# PIC32MZ2051W104132 device description
Architecture: MIPS; Family: PIC32MZW; Series: PIC32MZW
Registers are 32-bit, read-write, no defined reset value unless marked. A register's access mark holds for its fields unless they carry their own. Offsets are from the block's base; [hi:lo] are bit positions; {n}, {i} and the like mark numbered series; 'fields as' and 'values as' point back to an identical list.

## GPIO
Instances: GPIO 0x1f820000 in periph_pb2
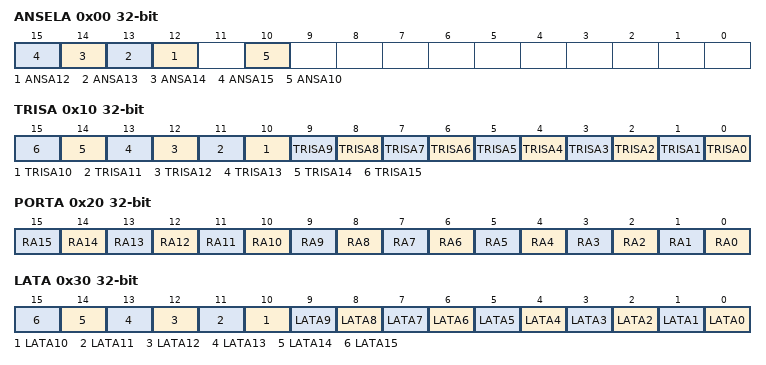
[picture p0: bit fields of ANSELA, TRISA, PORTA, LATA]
0x00 ANSELA
  [n] ANSA{n} (n=12..15), [10] ANSA10
0x10 TRISA
  [n] TRISA{n} (n=0..15)
0x20 PORTA
  [n] RA{n} (n=0..15)
0x30 LATA
  [n] LATA{n} (n=0..15)
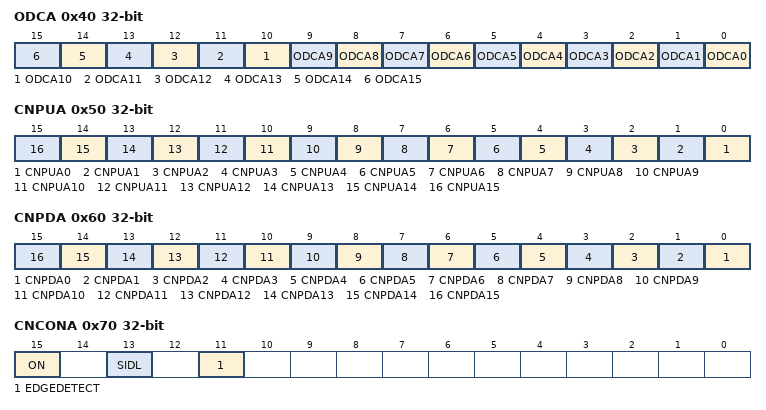
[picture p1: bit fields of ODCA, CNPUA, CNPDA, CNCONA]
0x40 ODCA
  [n] ODCA{n} (n=0..15)
0x50 CNPUA
  [n] CNPUA{n} (n=0..15)
0x60 CNPDA
  [n] CNPDA{n} (n=0..15)
0x70 CNCONA — Change Notice control for PORTx Register
  [15] ON — Change Notice Control ON bit
    1=CN is enabled; 0=CN is disabled
  [13] SIDL
  [11] EDGEDETECT — Change Notification Style bit
    1=Edge Style. Detect edge transitions (CNFx used for CN Event).; 0=Mismatch Style. Detect change from last PORTx read (CNSTATx used for CN Event).
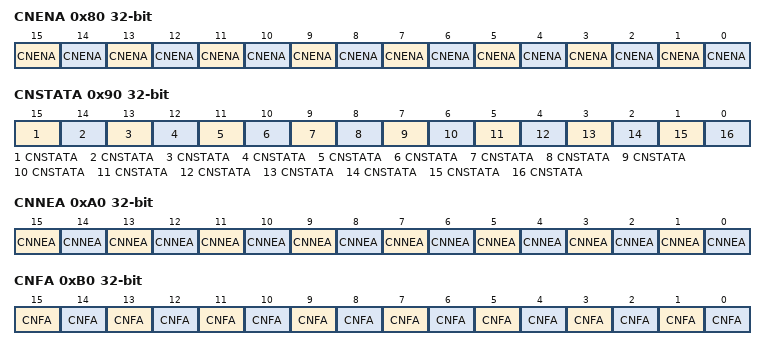
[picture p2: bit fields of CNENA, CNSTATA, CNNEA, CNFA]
0x80 CNENA
  [15] CNENA, [14] CNENA, [13] CNENA, [12] CNENA, [11] CNENA, [10] CNENA, [9] CNENA, [8] CNENA, [7] CNENA, [6] CNENA, [5] CNENA, [4] CNENA, [3] CNENA, [2] CNENA, [1] CNENA, [0] CNENA
0x90 CNSTATA
  [15] CNSTATA, [14] CNSTATA, [13] CNSTATA, [12] CNSTATA, [11] CNSTATA, [10] CNSTATA, [9] CNSTATA, [8] CNSTATA, [7] CNSTATA, [6] CNSTATA, [5] CNSTATA, [4] CNSTATA, [3] CNSTATA, [2] CNSTATA, [1] CNSTATA, [0] CNSTATA
0xA0 CNNEA
  [15] CNNEA, [14] CNNEA, [13] CNNEA, [12] CNNEA, [11] CNNEA, [10] CNNEA, [9] CNNEA, [8] CNNEA, [7] CNNEA, [6] CNNEA, [5] CNNEA, [4] CNNEA, [3] CNNEA, [2] CNNEA, [1] CNNEA, [0] CNNEA
0xB0 CNFA
  [15] CNFA, [14] CNFA, [13] CNFA, [12] CNFA, [11] CNFA, [10] CNFA, [9] CNFA, [8] CNFA, [7] CNFA, [6] CNFA, [5] CNFA, [4] CNFA, [3] CNFA, [2] CNFA, [1] CNFA, [0] CNFA
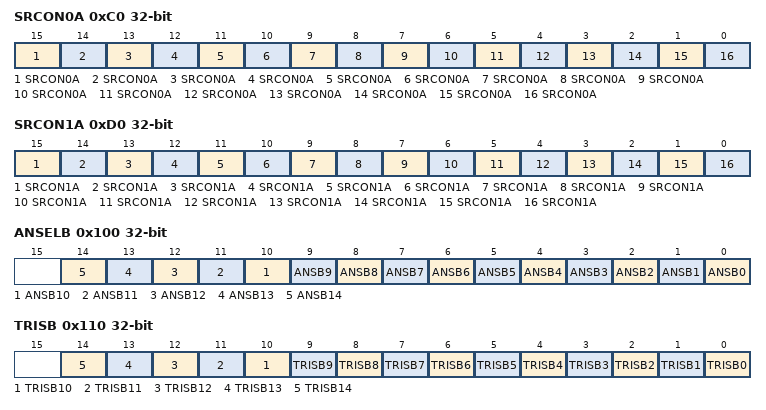
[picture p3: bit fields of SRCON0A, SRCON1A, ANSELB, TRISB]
0xC0 SRCON0A
  [15] SRCON0A, [14] SRCON0A, [13] SRCON0A, [12] SRCON0A, [11] SRCON0A, [10] SRCON0A, [9] SRCON0A, [8] SRCON0A, [7] SRCON0A, [6] SRCON0A, [5] SRCON0A, [4] SRCON0A, [3] SRCON0A, [2] SRCON0A, [1] SRCON0A, [0] SRCON0A
0xD0 SRCON1A
  [15] SRCON1A, [14] SRCON1A, [13] SRCON1A, [12] SRCON1A, [11] SRCON1A, [10] SRCON1A, [9] SRCON1A, [8] SRCON1A, [7] SRCON1A, [6] SRCON1A, [5] SRCON1A, [4] SRCON1A, [3] SRCON1A, [2] SRCON1A, [1] SRCON1A, [0] SRCON1A
0x100 ANSELB
  [n] ANSB{n} (n=0..14)
0x110 TRISB
  [n] TRISB{n} (n=0..14)
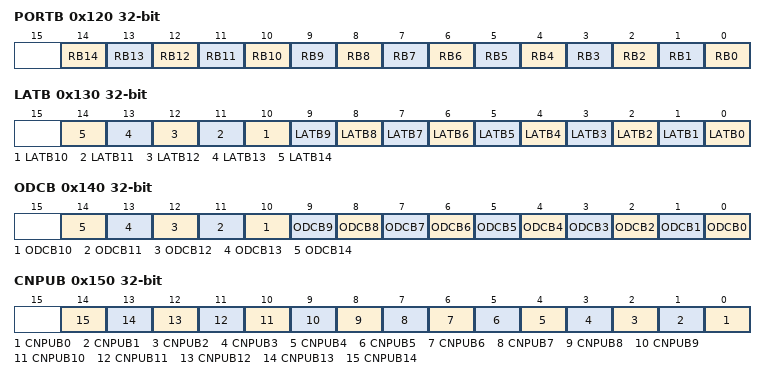
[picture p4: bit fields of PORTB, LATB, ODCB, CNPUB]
0x120 PORTB
  [n] RB{n} (n=0..14)
0x130 LATB
  [n] LATB{n} (n=0..14)
0x140 ODCB
  [n] ODCB{n} (n=0..14)
0x150 CNPUB
  [n] CNPUB{n} (n=0..14)
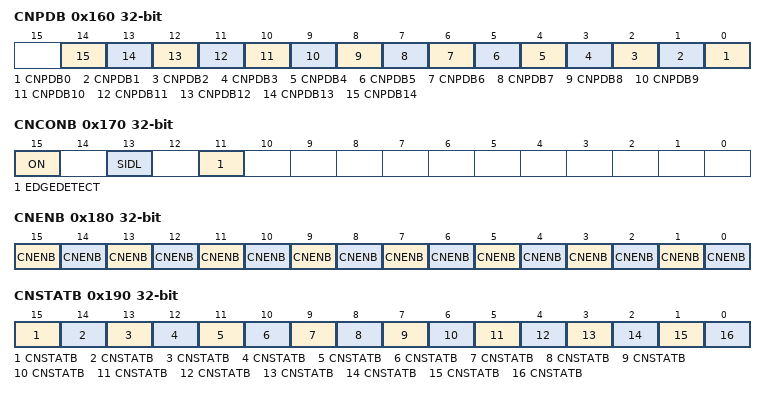
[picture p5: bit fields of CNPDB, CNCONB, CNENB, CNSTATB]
0x160 CNPDB
  [n] CNPDB{n} (n=0..14)
0x170 CNCONB — Change Notice control for PORTx Register
  fields as CNCONA
0x180 CNENB
  [15] CNENB, [14] CNENB, [13] CNENB, [12] CNENB, [11] CNENB, [10] CNENB, [9] CNENB, [8] CNENB, [7] CNENB, [6] CNENB, [5] CNENB, [4] CNENB, [3] CNENB, [2] CNENB, [1] CNENB, [0] CNENB
0x190 CNSTATB
  [15] CNSTATB, [14] CNSTATB, [13] CNSTATB, [12] CNSTATB, [11] CNSTATB, [10] CNSTATB, [9] CNSTATB, [8] CNSTATB, [7] CNSTATB, [6] CNSTATB, [5] CNSTATB, [4] CNSTATB, [3] CNSTATB, [2] CNSTATB, [1] CNSTATB, [0] CNSTATB
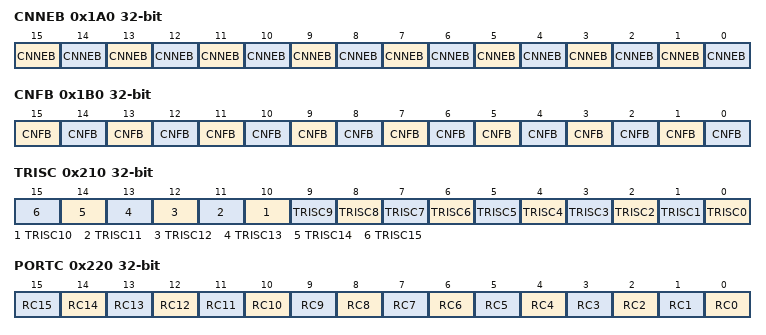
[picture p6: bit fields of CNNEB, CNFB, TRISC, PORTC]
0x1A0 CNNEB
  [15] CNNEB, [14] CNNEB, [13] CNNEB, [12] CNNEB, [11] CNNEB, [10] CNNEB, [9] CNNEB, [8] CNNEB, [7] CNNEB, [6] CNNEB, [5] CNNEB, [4] CNNEB, [3] CNNEB, [2] CNNEB, [1] CNNEB, [0] CNNEB
0x1B0 CNFB
  [15] CNFB, [14] CNFB, [13] CNFB, [12] CNFB, [11] CNFB, [10] CNFB, [9] CNFB, [8] CNFB, [7] CNFB, [6] CNFB, [5] CNFB, [4] CNFB, [3] CNFB, [2] CNFB, [1] CNFB, [0] CNFB
0x210 TRISC
  [n] TRISC{n} (n=0..15)
0x220 PORTC
  [n] RC{n} (n=0..15)
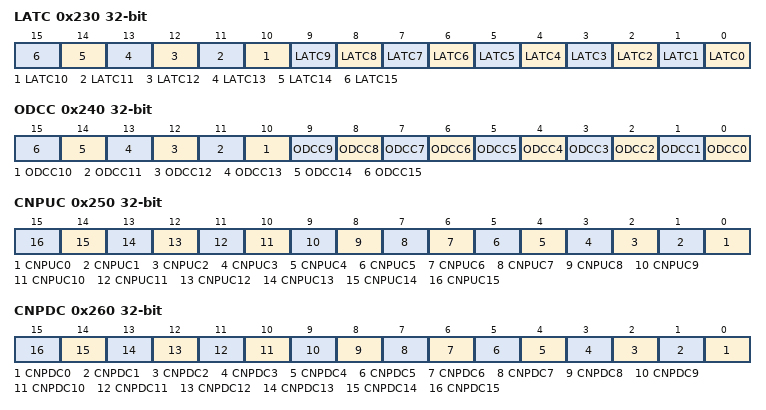
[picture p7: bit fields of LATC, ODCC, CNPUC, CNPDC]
0x230 LATC
  [n] LATC{n} (n=0..15)
0x240 ODCC
  [n] ODCC{n} (n=0..15)
0x250 CNPUC
  [n] CNPUC{n} (n=0..15)
0x260 CNPDC
  [n] CNPDC{n} (n=0..15)
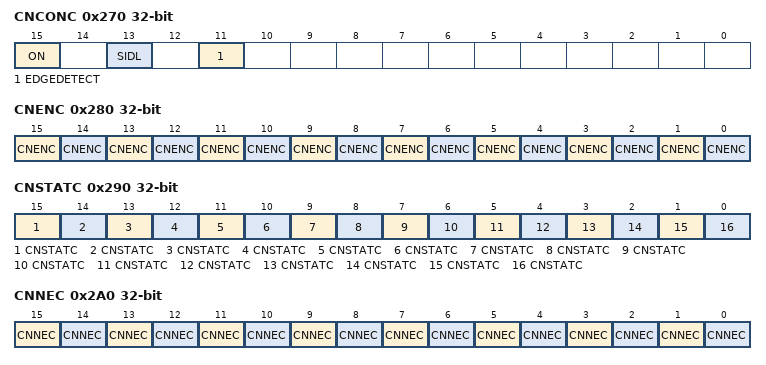
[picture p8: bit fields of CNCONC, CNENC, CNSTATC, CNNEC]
0x270 CNCONC — Change Notice control for PORTx Register
  fields as CNCONA
0x280 CNENC
  [15] CNENC, [14] CNENC, [13] CNENC, [12] CNENC, [11] CNENC, [10] CNENC, [9] CNENC, [8] CNENC, [7] CNENC, [6] CNENC, [5] CNENC, [4] CNENC, [3] CNENC, [2] CNENC, [1] CNENC, [0] CNENC
0x290 CNSTATC
  [15] CNSTATC, [14] CNSTATC, [13] CNSTATC, [12] CNSTATC, [11] CNSTATC, [10] CNSTATC, [9] CNSTATC, [8] CNSTATC, [7] CNSTATC, [6] CNSTATC, [5] CNSTATC, [4] CNSTATC, [3] CNSTATC, [2] CNSTATC, [1] CNSTATC, [0] CNSTATC
0x2A0 CNNEC
  [15] CNNEC, [14] CNNEC, [13] CNNEC, [12] CNNEC, [11] CNNEC, [10] CNNEC, [9] CNNEC, [8] CNNEC, [7] CNNEC, [6] CNNEC, [5] CNNEC, [4] CNNEC, [3] CNNEC, [2] CNNEC, [1] CNNEC, [0] CNNEC
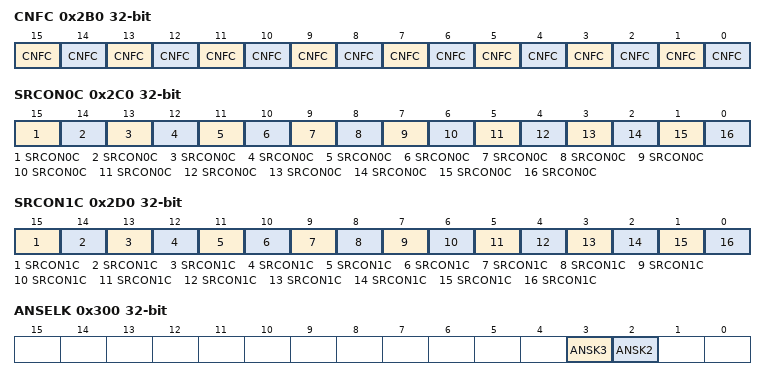
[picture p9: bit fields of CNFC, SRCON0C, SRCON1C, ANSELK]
0x2B0 CNFC
  [15] CNFC, [14] CNFC, [13] CNFC, [12] CNFC, [11] CNFC, [10] CNFC, [9] CNFC, [8] CNFC, [7] CNFC, [6] CNFC, [5] CNFC, [4] CNFC, [3] CNFC, [2] CNFC, [1] CNFC, [0] CNFC
0x2C0 SRCON0C
  [15] SRCON0C, [14] SRCON0C, [13] SRCON0C, [12] SRCON0C, [11] SRCON0C, [10] SRCON0C, [9] SRCON0C, [8] SRCON0C, [7] SRCON0C, [6] SRCON0C, [5] SRCON0C, [4] SRCON0C, [3] SRCON0C, [2] SRCON0C, [1] SRCON0C, [0] SRCON0C
0x2D0 SRCON1C
  [15] SRCON1C, [14] SRCON1C, [13] SRCON1C, [12] SRCON1C, [11] SRCON1C, [10] SRCON1C, [9] SRCON1C, [8] SRCON1C, [7] SRCON1C, [6] SRCON1C, [5] SRCON1C, [4] SRCON1C, [3] SRCON1C, [2] SRCON1C, [1] SRCON1C, [0] SRCON1C
0x300 ANSELK
  [3] ANSK3, [2] ANSK2
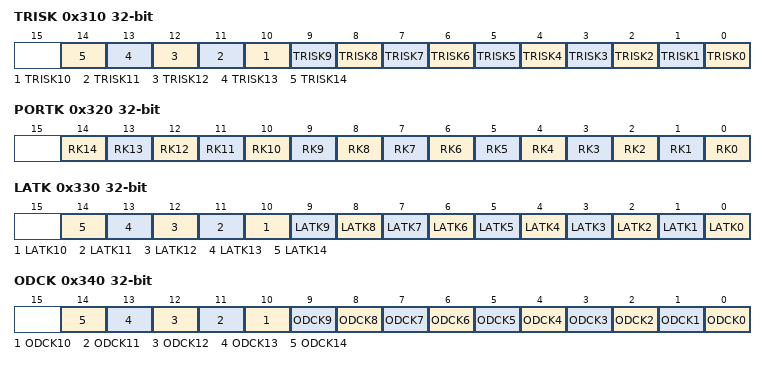
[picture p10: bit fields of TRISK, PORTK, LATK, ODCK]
0x310 TRISK
  [n] TRISK{n} (n=0..14)
0x320 PORTK
  [n] RK{n} (n=0..14)
0x330 LATK
  [n] LATK{n} (n=0..14)
0x340 ODCK
  [n] ODCK{n} (n=0..14)
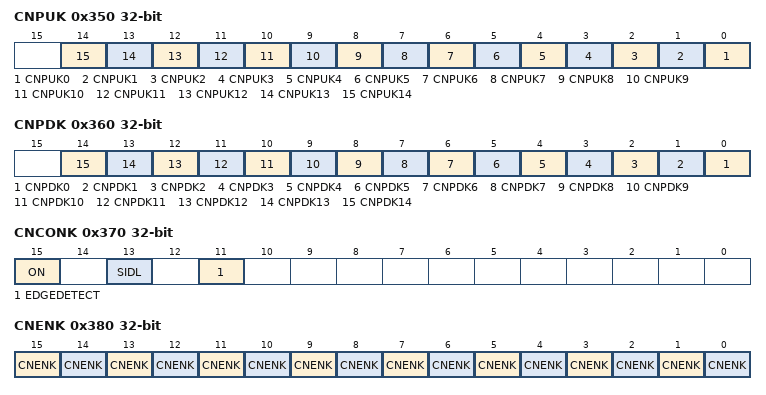
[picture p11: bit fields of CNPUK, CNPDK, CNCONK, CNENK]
0x350 CNPUK
  [n] CNPUK{n} (n=0..14)
0x360 CNPDK
  [n] CNPDK{n} (n=0..14)
0x370 CNCONK — Change Notice control for PORTx Register
  fields as CNCONA
0x380 CNENK
  [15] CNENK, [14] CNENK, [13] CNENK, [12] CNENK, [11] CNENK, [10] CNENK, [9] CNENK, [8] CNENK, [7] CNENK, [6] CNENK, [5] CNENK, [4] CNENK, [3] CNENK, [2] CNENK, [1] CNENK, [0] CNENK
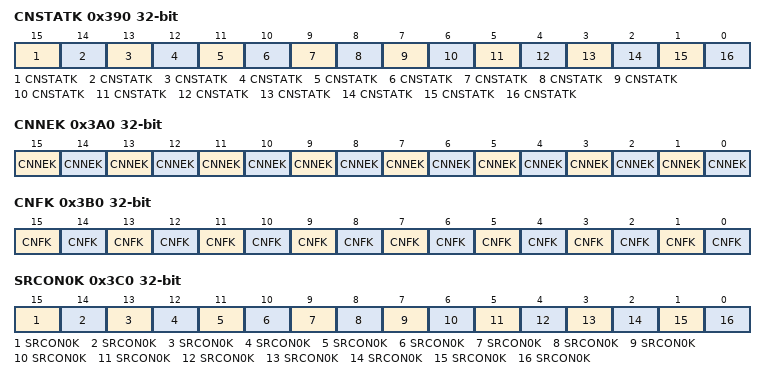
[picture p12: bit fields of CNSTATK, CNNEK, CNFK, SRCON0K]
0x390 CNSTATK
  [15] CNSTATK, [14] CNSTATK, [13] CNSTATK, [12] CNSTATK, [11] CNSTATK, [10] CNSTATK, [9] CNSTATK, [8] CNSTATK, [7] CNSTATK, [6] CNSTATK, [5] CNSTATK, [4] CNSTATK, [3] CNSTATK, [2] CNSTATK, [1] CNSTATK, [0] CNSTATK
0x3A0 CNNEK
  [15] CNNEK, [14] CNNEK, [13] CNNEK, [12] CNNEK, [11] CNNEK, [10] CNNEK, [9] CNNEK, [8] CNNEK, [7] CNNEK, [6] CNNEK, [5] CNNEK, [4] CNNEK, [3] CNNEK, [2] CNNEK, [1] CNNEK, [0] CNNEK
0x3B0 CNFK
  [15] CNFK, [14] CNFK, [13] CNFK, [12] CNFK, [11] CNFK, [10] CNFK, [9] CNFK, [8] CNFK, [7] CNFK, [6] CNFK, [5] CNFK, [4] CNFK, [3] CNFK, [2] CNFK, [1] CNFK, [0] CNFK
0x3C0 SRCON0K
  [15] SRCON0K, [14] SRCON0K, [13] SRCON0K, [12] SRCON0K, [11] SRCON0K, [10] SRCON0K, [9] SRCON0K, [8] SRCON0K, [7] SRCON0K, [6] SRCON0K, [5] SRCON0K, [4] SRCON0K, [3] SRCON0K, [2] SRCON0K, [1] SRCON0K, [0] SRCON0K
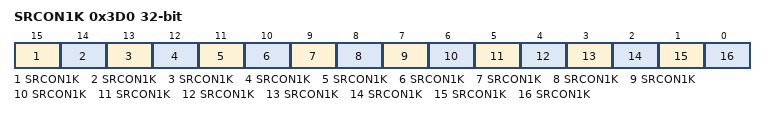
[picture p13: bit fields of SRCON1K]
0x3D0 SRCON1K
  [15] SRCON1K, [14] SRCON1K, [13] SRCON1K, [12] SRCON1K, [11] SRCON1K, [10] SRCON1K, [9] SRCON1K, [8] SRCON1K, [7] SRCON1K, [6] SRCON1K, [5] SRCON1K, [4] SRCON1K, [3] SRCON1K, [2] SRCON1K, [1] SRCON1K, [0] SRCON1K
